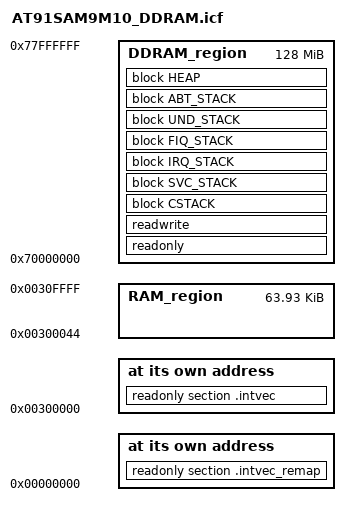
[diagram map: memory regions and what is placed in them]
/*###ICF### Section handled by ICF editor, don't touch! ****/
/*-Editor annotation file-*/
/* IcfEditorFile="$TOOLKIT_DIR$\config\ide\IcfEditor\a_v1_0.xml" */
/*-Specials-*/
define symbol __ICFEDIT_intvec_start__       = 0x00300000;
/*-Memory Regions-*/
define symbol __ICFEDIT_region_RAM_start__   = 0x00300044;
define symbol __ICFEDIT_region_RAM_end__     = 0x0030FFFF;
define symbol __ICFEDIT_region_DDRAM_start__ = 0x70000000;
define symbol __ICFEDIT_region_DDRAM_end__   = 0x77FFFFFF;
/*-Sizes-*/
define symbol __ICFEDIT_size_cstack__   = 0x400;
define symbol __ICFEDIT_size_svcstack__ = 0x400;
define symbol __ICFEDIT_size_irqstack__ = 0x40;
define symbol __ICFEDIT_size_fiqstack__ = 0x40;
define symbol __ICFEDIT_size_undstack__ = 0x40;
define symbol __ICFEDIT_size_abtstack__ = 0x40;
define symbol __ICFEDIT_size_heap__     = 0x100;
/**** End of ICF editor section. ###ICF###*/


define memory mem with size = 4G;
define region RAM_region        = mem:[from __ICFEDIT_region_RAM_start__ to __ICFEDIT_region_RAM_end__];
define region DDRAM_region      = mem:[from __ICFEDIT_region_DDRAM_start__ to __ICFEDIT_region_DDRAM_end__];

define block CSTACK    with alignment = 8, size = __ICFEDIT_size_cstack__   { };
define block SVC_STACK with alignment = 8, size = __ICFEDIT_size_svcstack__ { };
define block IRQ_STACK with alignment = 8, size = __ICFEDIT_size_irqstack__ { };
define block FIQ_STACK with alignment = 8, size = __ICFEDIT_size_fiqstack__ { };
define block UND_STACK with alignment = 8, size = __ICFEDIT_size_undstack__ { };
define block ABT_STACK with alignment = 8, size = __ICFEDIT_size_abtstack__ { };
define block HEAP      with alignment = 8, size = __ICFEDIT_size_heap__     { };

initialize by copy { readwrite };
do not initialize  { section .noinit };

place at address mem:__ICFEDIT_intvec_start__    { readonly section .intvec };

define symbol __ICFEDIT_intvec_remap_start__ = 0x00000000;
place at address mem:__ICFEDIT_intvec_remap_start__
                                                 { readonly section .intvec_remap };

place in DDRAM_region { readonly };
place in DDRAM_region { readwrite,
                        block CSTACK, block SVC_STACK, block IRQ_STACK, block FIQ_STACK,
                        block UND_STACK, block ABT_STACK, block HEAP };

define exported symbol fl_sdram_end = (__ICFEDIT_region_RAM_end__ & 0xFFFFFFF8);
